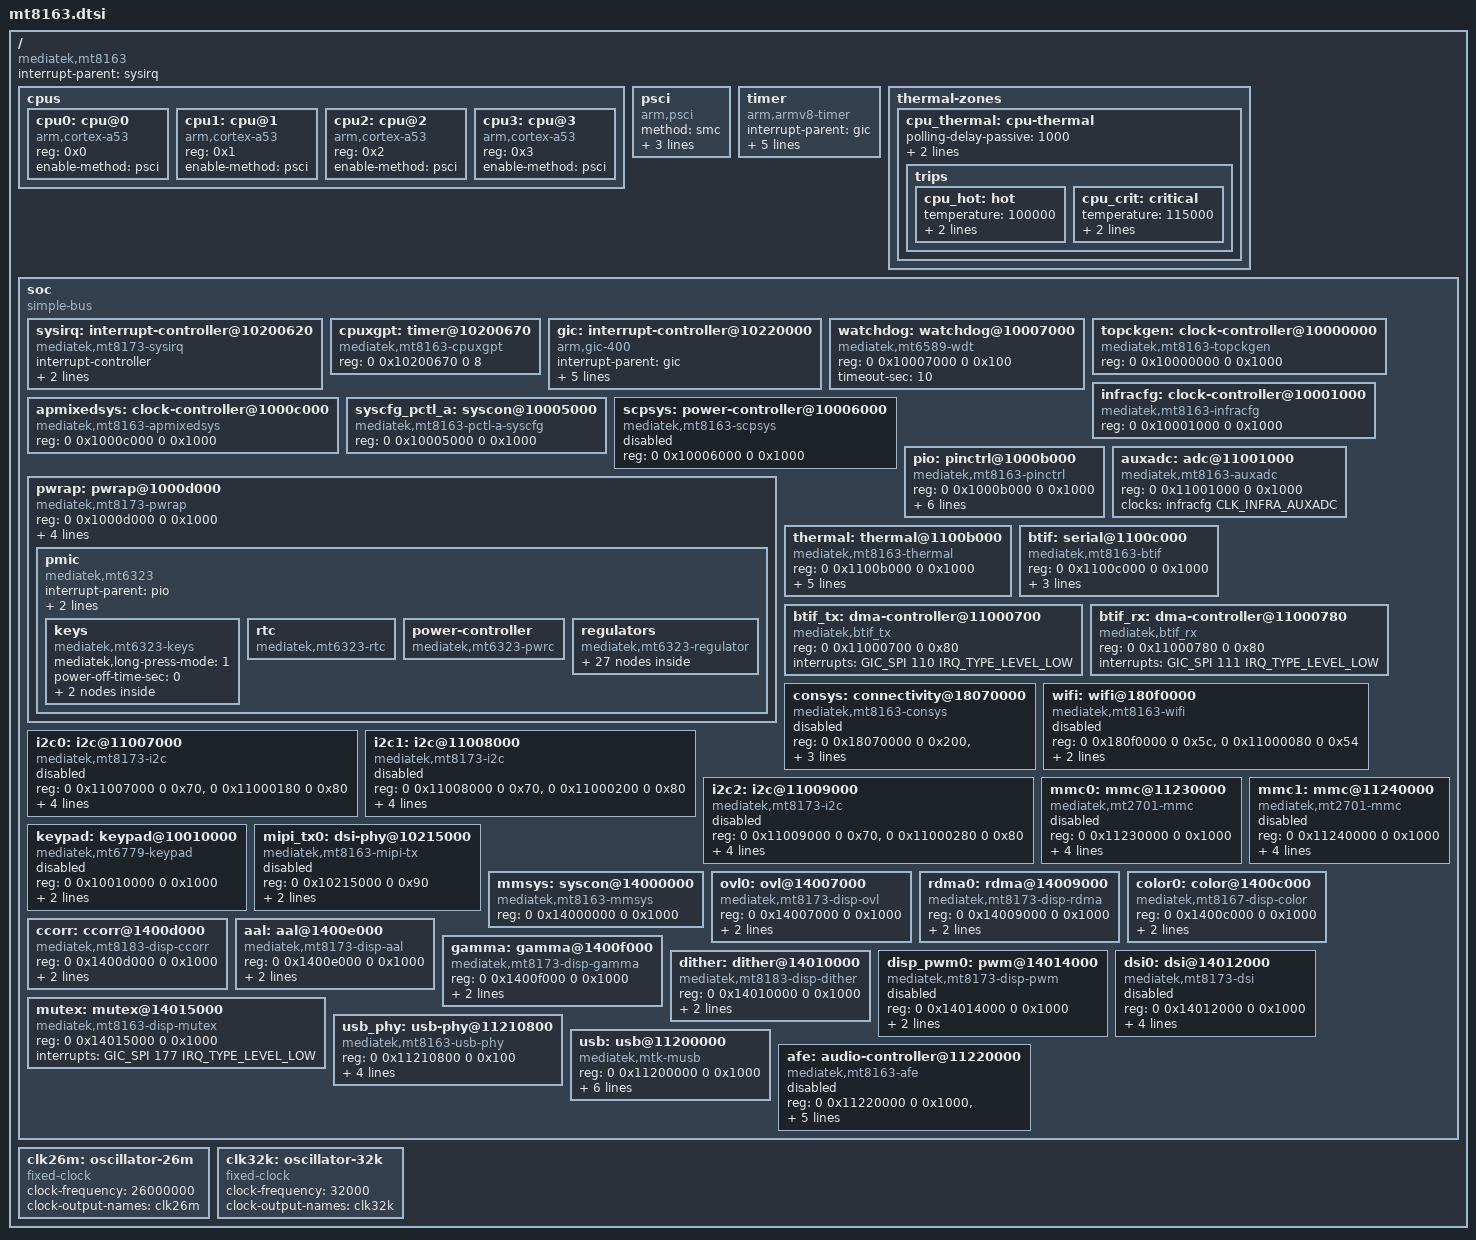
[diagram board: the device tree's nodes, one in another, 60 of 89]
// SPDX-License-Identifier: GPL-2.0
/*
 * MediaTek MT8163 SoC (quad Cortex-A53). Minimal description, grown stage by stage.
 * Register addresses taken from the vendor device tree (Teclast P80h stock kernel);
 * node layout follows mainline mt8173.dtsi.
 */
#include <dt-bindings/clock/mt8163-clk.h>
#include <dt-bindings/reset/mt8173-resets.h>
#include <dt-bindings/interrupt-controller/arm-gic.h>
#include <dt-bindings/interrupt-controller/irq.h>

/ {
	compatible = "mediatek,mt8163";
	interrupt-parent = <&sysirq>;
	#address-cells = <2>;
	#size-cells = <2>;

	cpus {
		#address-cells = <1>;
		#size-cells = <0>;

		cpu0: cpu@0 { device_type = "cpu"; compatible = "arm,cortex-a53"; reg = <0x0>; enable-method = "psci"; };
		cpu1: cpu@1 { device_type = "cpu"; compatible = "arm,cortex-a53"; reg = <0x1>; enable-method = "psci"; };
		cpu2: cpu@2 { device_type = "cpu"; compatible = "arm,cortex-a53"; reg = <0x2>; enable-method = "psci"; };
		cpu3: cpu@3 { device_type = "cpu"; compatible = "arm,cortex-a53"; reg = <0x3>; enable-method = "psci"; };
	};

	/* ATF (tee1) speaks PSCI 0.1 with the stock DT's function IDs; it only sets the entry point, the core's MTCMOS
	 * is switched by drivers/soc/mediatek/mt8163-cpu-power.c as stock mt_psci_cpu_boot does. */
	psci {
		compatible = "arm,psci";
		method = "smc";
		cpu_suspend = <0x84000001>;
		cpu_off = <0x84000002>;
		cpu_on = <0x84000003>;
	};

	timer {
		compatible = "arm,armv8-timer";
		interrupt-parent = <&gic>;
		interrupts = <GIC_PPI 13 IRQ_TYPE_LEVEL_LOW>, <GIC_PPI 14 IRQ_TYPE_LEVEL_LOW>,
			     <GIC_PPI 11 IRQ_TYPE_LEVEL_LOW>, <GIC_PPI 10 IRQ_TYPE_LEVEL_LOW>;
		clock-frequency = <13000000>;
	};

	thermal-zones {
		cpu_thermal: cpu-thermal {
			polling-delay-passive = <1000>;
			polling-delay = <2000>;
			thermal-sensors = <&thermal 0>;

			trips {
				cpu_hot: hot {
					temperature = <100000>;
					hysteresis = <2000>;
					type = "hot";
				};
				cpu_crit: critical {
					temperature = <115000>;
					hysteresis = <2000>;
					type = "critical";
				};
			};
		};
	};

	soc {
		compatible = "simple-bus";
		#address-cells = <2>;
		#size-cells = <2>;
		ranges;

		/* MediaTek interrupt polarity inverter in front of the GIC */
		sysirq: interrupt-controller@10200620 {
			compatible = "mediatek,mt8173-sysirq", "mediatek,mt6577-sysirq";
			interrupt-controller;
			#interrupt-cells = <3>;
			interrupt-parent = <&gic>;
			reg = <0 0x10200620 0 0x20>;
		};

		/* index/data pair inside mcucfg that enables the generic timer counter */
		cpuxgpt: timer@10200670 {
			compatible = "mediatek,mt8163-cpuxgpt";
			reg = <0 0x10200670 0 8>;
		};

		gic: interrupt-controller@10220000 {
			compatible = "arm,gic-400";
			#interrupt-cells = <3>;
			interrupt-parent = <&gic>;
			interrupt-controller;
			reg = <0 0x10221000 0 0x1000>, <0 0x10222000 0 0x2000>,
			      <0 0x10224000 0 0x2000>, <0 0x10226000 0 0x2000>;
			interrupts = <GIC_PPI 9 IRQ_TYPE_LEVEL_HIGH>;
		};

		watchdog: watchdog@10007000 {
			compatible = "mediatek,mt6589-wdt";
			reg = <0 0x10007000 0 0x100>;
			/* no interrupt: the GIC rejects the falling edge (needs the sysirq polarity wrapper) and the probe fails with -EINVAL */
			timeout-sec = <10>;
		};

		topckgen: clock-controller@10000000 {
			compatible = "mediatek,mt8163-topckgen";
			reg = <0 0x10000000 0 0x1000>;
			#clock-cells = <1>;
		};

		infracfg: clock-controller@10001000 {
			compatible = "mediatek,mt8163-infracfg", "syscon";
			reg = <0 0x10001000 0 0x1000>;
			#clock-cells = <1>;
			#reset-cells = <1>;
		};

		apmixedsys: clock-controller@1000c000 {
			compatible = "mediatek,mt8163-apmixedsys";
			reg = <0 0x1000c000 0 0x1000>;
			#clock-cells = <1>;
		};

		syscfg_pctl_a: syscon@10005000 {
			compatible = "mediatek,mt8163-pctl-a-syscfg", "syscon";
			reg = <0 0x10005000 0 0x1000>;
		};

		/* SPM; only looked up (not probed) by mt8163-cpu-power for the CPU MTCMOS, the AFE maps it too */
		scpsys: power-controller@10006000 {
			compatible = "mediatek,mt8163-scpsys";
			reg = <0 0x10006000 0 0x1000>;
			status = "disabled";
		};

		pio: pinctrl@1000b000 {
			compatible = "mediatek,mt8163-pinctrl";
			reg = <0 0x1000b000 0 0x1000>;
			mediatek,pctl-regmap = <&syscfg_pctl_a>;
			gpio-controller;
			#gpio-cells = <2>;
			interrupt-controller;
			#interrupt-cells = <2>;
			interrupts = <GIC_SPI 153 IRQ_TYPE_LEVEL_HIGH>,
				     <GIC_SPI 154 IRQ_TYPE_LEVEL_HIGH>,
				     <GIC_SPI 155 IRQ_TYPE_LEVEL_HIGH>;
		};

		pwrap: pwrap@1000d000 {
			compatible = "mediatek,mt8173-pwrap";
			reg = <0 0x1000d000 0 0x1000>;
			reg-names = "pwrap";
			interrupts = <GIC_SPI 161 IRQ_TYPE_LEVEL_HIGH>;
			resets = <&infracfg MT8173_INFRA_PMIC_WRAP_RST>;
			reset-names = "pwrap";
			clocks = <&topckgen CLK_TOP_PMICSPI_SEL>, <&infracfg CLK_INFRA_PMIC_AP>;
			clock-names = "spi", "wrap";

			pmic: pmic {
				compatible = "mediatek,mt6323";
				interrupt-parent = <&pio>;
				interrupts = <24 IRQ_TYPE_LEVEL_HIGH>;	/* stock PMIC_EINT_SETTING: mt_eint_registration(24, level high); 150 floats and storms */
				interrupt-controller;
				#interrupt-cells = <2>;

				keys {
					compatible = "mediatek,mt6323-keys";
					mediatek,long-press-mode = <1>;
					power-off-time-sec = <0>;
					power {
						linux,keycodes = <116>;
						wakeup-source;
					};
					/* stock kpd_pmic_rstkey_hal reports the PMIC home key as KEY_VOLUMEDOWN */
					home {
						linux,keycodes = <114>;
					};
				};

				rtc {
					compatible = "mediatek,mt6323-rtc";
				};

				power-controller {
					compatible = "mediatek,mt6323-pwrc";
				};

				regulators {
					compatible = "mediatek,mt6323-regulator";
					mt6323_vproc_reg: buck_vproc {
						regulator-always-on;
					};
					mt6323_vsys_reg: buck_vsys {
						regulator-always-on;
					};
					mt6323_vpa_reg: buck_vpa {
						regulator-always-on;
					};
					mt6323_vtcxo_reg: ldo_vtcxo {
						regulator-always-on;
					};
					mt6323_va_reg: ldo_va {
						regulator-always-on;
					};
					mt6323_vio28_reg: ldo_vio28 {
						regulator-always-on;
					};
					mt6323_vemc3v3_reg: ldo_vemc3v3 {
						regulator-always-on;
					};
					mt6323_vrtc_reg: ldo_vrtc {
						regulator-always-on;
					};
					mt6323_vm_reg: ldo_vm {
						regulator-always-on;
					};
					mt6323_vio18_reg: ldo_vio18 {
						regulator-always-on;
					};
					mt6323_vcn28_reg: ldo_vcn28 {
					};
					mt6323_vcn33_bt_reg: ldo_vcn33_bt {
					};
					mt6323_vcn33_wifi_reg: ldo_vcn33_wifi {
					};
					mt6323_vcama_reg: ldo_vcama {
					};
					mt6323_vusb_reg: ldo_vusb {
					};
					mt6323_vmc_reg: ldo_vmc {
					};
					mt6323_vmch_reg: ldo_vmch {
					};
					mt6323_vgp1_reg: ldo_vgp1 {
					};
					mt6323_vgp2_reg: ldo_vgp2 {
					};
					mt6323_vgp3_reg: ldo_vgp3 {
					};
					mt6323_vcn18_reg: ldo_vcn18 {
					};
					mt6323_vsim1_reg: ldo_vsim1 {
					};
					mt6323_vsim2_reg: ldo_vsim2 {
					};
					mt6323_vcamaf_reg: ldo_vcamaf {
					};
					mt6323_vibr_reg: ldo_vibr {
					};
					mt6323_vrf18_reg: ldo_vrf18 {
					};
					mt6323_vcamd_reg: ldo_vcamd {
					};
				};
			};
		};

		/* only referenced by the thermal controller (TS readings go through AUXADC channel 11) */
		auxadc: adc@11001000 {
			compatible = "mediatek,mt8163-auxadc", "mediatek,mt8173-auxadc";
			reg = <0 0x11001000 0 0x1000>;
			clocks = <&infracfg CLK_INFRA_AUXADC>;
			clock-names = "main";
			#io-channel-cells = <1>;
		};

		thermal: thermal@1100b000 {
			compatible = "mediatek,mt8163-thermal";
			reg = <0 0x1100b000 0 0x1000>;
			interrupts = <GIC_SPI 78 IRQ_TYPE_LEVEL_LOW>;
			clocks = <&infracfg CLK_INFRA_THERM>, <&infracfg CLK_INFRA_AUXADC>;
			clock-names = "therm", "auxadc";
			mediatek,auxadc = <&auxadc>;
			mediatek,apmixedsys = <&apmixedsys>;
			#thermal-sensor-cells = <1>;
		};

		/* CONSYS (Wi-Fi/BT/GPS/FM combo core on die, MT6627-class RF), all from the stock DT and kernel:
		 * BTIF is the AP<->CONSYS UART-like link (STP/WMT), its APDMA channels, and the Wi-Fi AHB window. */
		btif: serial@1100c000 {
			compatible = "mediatek,mt8163-btif", "mediatek,btif";
			reg = <0 0x1100c000 0 0x1000>;
			interrupts = <GIC_SPI 112 IRQ_TYPE_LEVEL_LOW>;
			clocks = <&infracfg CLK_INFRA_BTIF>, <&infracfg CLK_INFRA_AP_DMA>;
			clock-names = "btifc", "apdmac";
		};

		btif_tx: dma-controller@11000700 {
			compatible = "mediatek,btif_tx";
			reg = <0 0x11000700 0 0x80>;
			interrupts = <GIC_SPI 110 IRQ_TYPE_LEVEL_LOW>;
		};

		btif_rx: dma-controller@11000780 {
			compatible = "mediatek,btif_rx";
			reg = <0 0x11000780 0 0x80>;
			interrupts = <GIC_SPI 111 IRQ_TYPE_LEVEL_LOW>;
		};

		/* reg: CONN MCU config, TOPRGU, TOPCKGEN + INFRACFG (EMI remap 0x10001320), SPM (CONN MTCMOS 0x280) */
		consys: connectivity@18070000 {
			compatible = "mediatek,mt8163-consys";
			reg = <0 0x18070000 0 0x200>, <0 0x10007000 0 0x100>,
			      <0 0x10000000 0 0x2000>, <0 0x10006000 0 0x1000>;
			interrupts = <GIC_SPI 237 IRQ_TYPE_LEVEL_LOW>;
			status = "disabled";
		};

		wifi: wifi@180f0000 {
			compatible = "mediatek,mt8163-wifi", "mediatek,wifi";
			reg = <0 0x180f0000 0 0x5c>, <0 0x11000080 0 0x54>;	/* AHB window, HIF APDMA channel */
			interrupts = <GIC_SPI 238 IRQ_TYPE_LEVEL_LOW>;
			clocks = <&infracfg CLK_INFRA_AP_DMA>;
			clock-names = "wifi-dma";
			status = "disabled";
		};

		i2c0: i2c@11007000 {
			compatible = "mediatek,mt8173-i2c";
			reg = <0 0x11007000 0 0x70>, <0 0x11000180 0 0x80>;
			interrupts = <GIC_SPI 84 IRQ_TYPE_LEVEL_LOW>;
			clock-div = <8>;
			clocks = <&infracfg CLK_INFRA_I2C0>, <&infracfg CLK_INFRA_AP_DMA>;
			clock-names = "main", "dma";
			#address-cells = <1>;
			#size-cells = <0>;
			status = "disabled";
		};

		i2c1: i2c@11008000 {
			compatible = "mediatek,mt8173-i2c";
			reg = <0 0x11008000 0 0x70>, <0 0x11000200 0 0x80>;
			interrupts = <GIC_SPI 85 IRQ_TYPE_LEVEL_LOW>;
			clock-div = <8>;
			clocks = <&infracfg CLK_INFRA_I2C1>, <&infracfg CLK_INFRA_AP_DMA>;
			clock-names = "main", "dma";
			#address-cells = <1>;
			#size-cells = <0>;
			status = "disabled";
		};

		i2c2: i2c@11009000 {
			compatible = "mediatek,mt8173-i2c";
			reg = <0 0x11009000 0 0x70>, <0 0x11000280 0 0x80>;
			interrupts = <GIC_SPI 86 IRQ_TYPE_LEVEL_LOW>;
			clock-div = <10>;
			clocks = <&infracfg CLK_INFRA_I2C2>, <&infracfg CLK_INFRA_AP_DMA>;
			clock-names = "main", "dma";
			#address-cells = <1>;
			#size-cells = <0>;
			status = "disabled";
		};

		mmc0: mmc@11230000 {
			compatible = "mediatek,mt2701-mmc";	/* same controller revision as the vendor mt8163 tag */
			reg = <0 0x11230000 0 0x1000>;
			interrupts = <GIC_SPI 79 IRQ_TYPE_LEVEL_LOW>;
			clocks = <&topckgen CLK_TOP_MSDC30_0_SEL>, <&infracfg CLK_INFRA_MSDC0>, <&infracfg CLK_INFRA_MSDC3>;
			clock-names = "source", "hclk", "source_cg";
			status = "disabled";
		};

		mmc1: mmc@11240000 {
			compatible = "mediatek,mt2701-mmc";
			reg = <0 0x11240000 0 0x1000>;
			interrupts = <GIC_SPI 80 IRQ_TYPE_LEVEL_LOW>;
			clocks = <&topckgen CLK_TOP_MSDC30_1_SEL>, <&infracfg CLK_INFRA_MSDC1>, <&infracfg CLK_INFRA_MSDC3>;
			clock-names = "source", "hclk", "source_cg";
			status = "disabled";
		};

		/*
		 * Display. Addresses from the stock DT, IRQs from the stock /proc/interrupts; register maps checked against the vendor
		 * dispsys headers: OVL/RDMA/DSI = mt8173 layout, routing = mt8167, mutex/mm gates MT8163-own.
		 * No IOMMU: LK runs with M4U off and larb0 MMU_EN = 0, buffers come from CMA.
		 */
		/* same IP as mt6779 (vendor hal_kpd.h: MEM 0x04, DEBOUNCE 0x18, SEL 0x20, EN 0x24); stock DT: SPI 162 falling */
		keypad: keypad@10010000 {
			compatible = "mediatek,mt6779-keypad";
			reg = <0 0x10010000 0 0x1000>;
			interrupts = <GIC_SPI 162 IRQ_TYPE_EDGE_FALLING>;
			clocks = <&clk32k>;
			clock-names = "kpd";
			status = "disabled";
		};

		mipi_tx0: dsi-phy@10215000 {
			compatible = "mediatek,mt8163-mipi-tx";
			reg = <0 0x10215000 0 0x90>;
			clocks = <&clk26m>;
			clock-output-names = "mipi_tx0_pll";
			#clock-cells = <0>;
			#phy-cells = <0>;
			status = "disabled";
		};

		mmsys: syscon@14000000 {
			compatible = "mediatek,mt8163-mmsys", "syscon";
			reg = <0 0x14000000 0 0x1000>;
			#clock-cells = <1>;
			#reset-cells = <1>;
		};

		ovl0: ovl@14007000 {
			compatible = "mediatek,mt8173-disp-ovl";
			reg = <0 0x14007000 0 0x1000>;
			interrupts = <GIC_SPI 184 IRQ_TYPE_LEVEL_LOW>;
			clocks = <&mmsys CLK_MM_DISP_OVL0>;
		};

		rdma0: rdma@14009000 {
			compatible = "mediatek,mt8173-disp-rdma";
			reg = <0 0x14009000 0 0x1000>;
			interrupts = <GIC_SPI 186 IRQ_TYPE_LEVEL_LOW>;	/* stock /proc/interrupts: GIC 218 = SPI 186 is the RDMA0 vsync; the stock DT says 0xc7, which is wrong */
			clocks = <&mmsys CLK_MM_DISP_RDMA0>;
		};

		color0: color@1400c000 {
			compatible = "mediatek,mt8167-disp-color";
			reg = <0 0x1400c000 0 0x1000>;
			interrupts = <GIC_SPI 189 IRQ_TYPE_LEVEL_LOW>;
			clocks = <&mmsys CLK_MM_DISP_COLOR>;
		};

		ccorr: ccorr@1400d000 {
			compatible = "mediatek,mt8183-disp-ccorr";
			reg = <0 0x1400d000 0 0x1000>;
			interrupts = <GIC_SPI 190 IRQ_TYPE_LEVEL_LOW>;
			clocks = <&mmsys CLK_MM_DISP_CCORR>;
		};

		aal: aal@1400e000 {
			compatible = "mediatek,mt8173-disp-aal";
			reg = <0 0x1400e000 0 0x1000>;
			interrupts = <GIC_SPI 191 IRQ_TYPE_LEVEL_LOW>;
			clocks = <&mmsys CLK_MM_DISP_AAL>;
		};

		gamma: gamma@1400f000 {
			compatible = "mediatek,mt8173-disp-gamma";
			reg = <0 0x1400f000 0 0x1000>;
			interrupts = <GIC_SPI 192 IRQ_TYPE_LEVEL_LOW>;
			clocks = <&mmsys CLK_MM_DISP_GAMMA>;
		};

		dither: dither@14010000 {
			compatible = "mediatek,mt8183-disp-dither";
			reg = <0 0x14010000 0 0x1000>;
			interrupts = <GIC_SPI 193 IRQ_TYPE_LEVEL_LOW>;
			clocks = <&mmsys CLK_MM_DISP_DITHER>;
		};

		disp_pwm0: pwm@14014000 {
			compatible = "mediatek,mt8173-disp-pwm", "mediatek,mt6595-disp-pwm";
			reg = <0 0x14014000 0 0x1000>;
			#pwm-cells = <2>;
			clocks = <&mmsys CLK_MM_DISP_PWM_MM>, <&mmsys CLK_MM_DISP_PWM_26M>;
			clock-names = "main", "mm";
			status = "disabled";
		};

		dsi0: dsi@14012000 {
			compatible = "mediatek,mt8173-dsi";
			reg = <0 0x14012000 0 0x1000>;
			interrupts = <GIC_SPI 195 IRQ_TYPE_LEVEL_LOW>;
			clocks = <&mmsys CLK_MM_DSI_ENGINE>, <&mmsys CLK_MM_DSI_DIGITAL>, <&mipi_tx0>;
			clock-names = "engine", "digital", "hs";
			phys = <&mipi_tx0>;
			phy-names = "dphy";
			status = "disabled";
		};

		mutex: mutex@14015000 {
			compatible = "mediatek,mt8163-disp-mutex";
			reg = <0 0x14015000 0 0x1000>;
			interrupts = <GIC_SPI 177 IRQ_TYPE_LEVEL_LOW>;
		};

		usb_phy: usb-phy@11210800 {
			compatible = "mediatek,mt8163-usb-phy";
			reg = <0 0x11210800 0 0x100>;
			clocks = <&apmixedsys CLK_APMIXED_UNIVPLL>, <&infracfg CLK_INFRA_ICUSB>, <&infracfg CLK_INFRA_USB>, <&infracfg CLK_INFRA_USB_MCU>;
			clock-names = "univpll", "icusb", "main", "mcu";
			#phy-cells = <0>;
		};

		usb: usb@11200000 {
			compatible = "mediatek,mtk-musb";
			reg = <0 0x11200000 0 0x1000>;
			interrupts = <GIC_SPI 72 IRQ_TYPE_LEVEL_LOW>;
			interrupt-names = "mc";
			phys = <&usb_phy>;
			dr_mode = "peripheral";
			clocks = <&infracfg CLK_INFRA_USB>, <&infracfg CLK_INFRA_USB_MCU>, <&apmixedsys CLK_APMIXED_UNIVPLL>;
			clock-names = "main", "mcu", "univpll";
		};

		/*
		 * Audio front end. Stock DT AUDIO@0x11220000 SPI 142 (stock /proc/interrupts: GIC 174 Afe_ISR_Handle);
		 * the second reg is SPM, mapped (not claimed) to power the audio MTCMOS as stock spm_mtcmos_ctrl_aud.
		 */
		afe: audio-controller@11220000 {
			compatible = "mediatek,mt8163-afe";
			reg = <0 0x11220000 0 0x1000>, <0 0x10006000 0 0x1000>;
			reg-names = "afe", "spm";
			interrupts = <GIC_SPI 142 IRQ_TYPE_LEVEL_LOW>;
			clocks = <&infracfg CLK_INFRA_AUDIO>, <&topckgen CLK_TOP_AUDIO_SEL>,
				 <&topckgen CLK_TOP_AUD_INTBUS_SEL>;
			clock-names = "infra", "top", "intbus";
			#sound-dai-cells = <0>;
			status = "disabled";
		};
	};

	clk26m: oscillator-26m {
		compatible = "fixed-clock";
		#clock-cells = <0>;
		clock-frequency = <26000000>;
		clock-output-names = "clk26m";
	};

	clk32k: oscillator-32k {
		compatible = "fixed-clock";
		#clock-cells = <0>;
		clock-frequency = <32000>;
		clock-output-names = "clk32k";
	};
};
